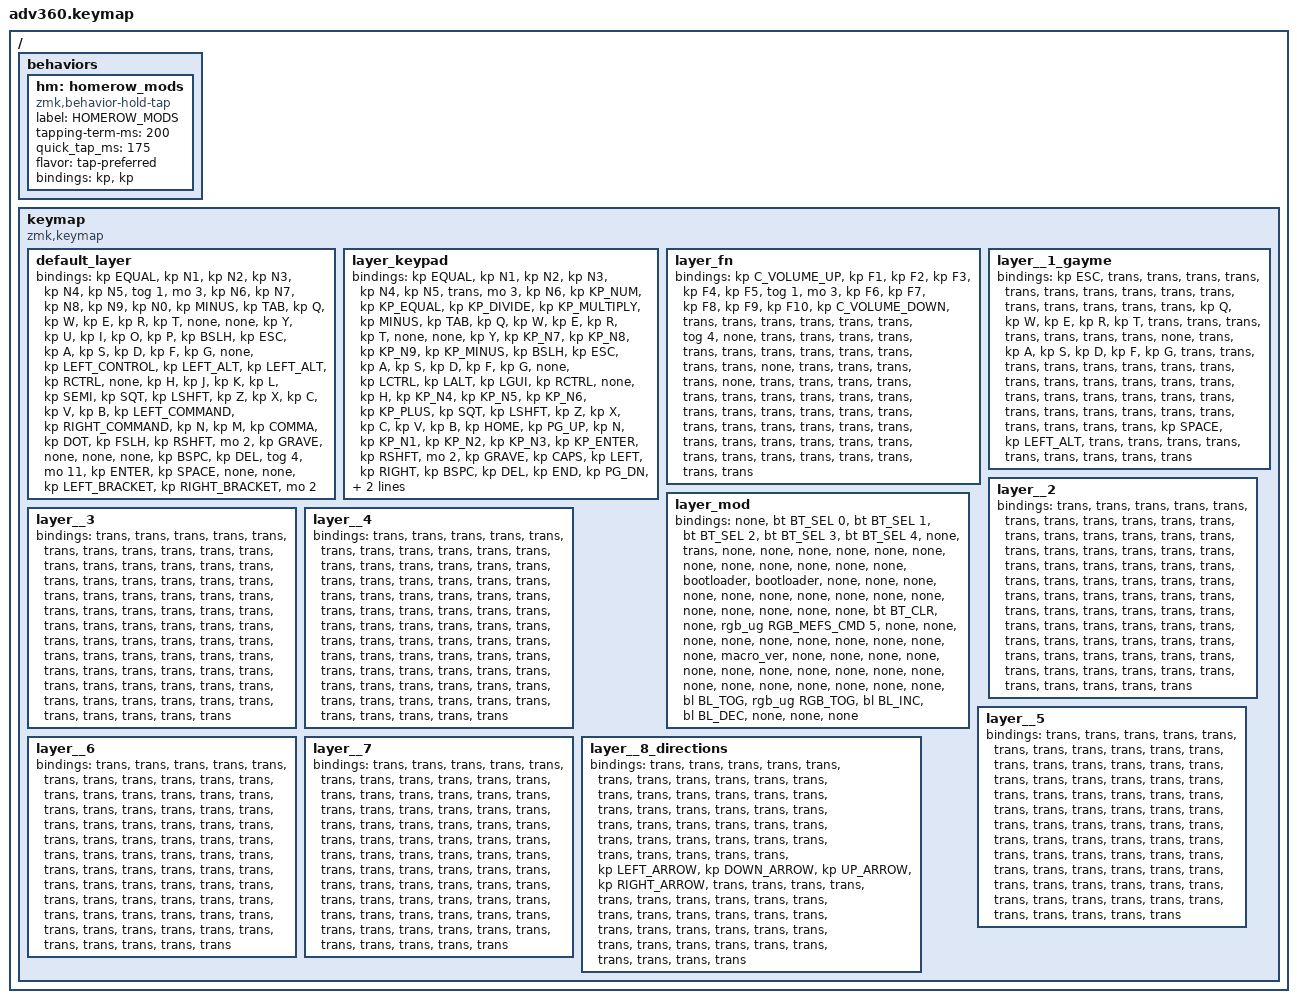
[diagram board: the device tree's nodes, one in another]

/*
 * Copyright (c) 2020 The ZMK Contributors
 *
 * SPDX-License-Identifier: MIT
 */


/* THIS FILE WAS GENERATED!
 *
 * This file was generated automatically. You may or may not want to
 * edit it directly.
 */

#include <behaviors.dtsi>
#include <dt-bindings/zmk/keys.h>
#include <dt-bindings/zmk/bt.h>
#include <dt-bindings/zmk/rgb.h>
#include <dt-bindings/zmk/backlight.h>

/ {
  behaviors {
    #include "macros.dtsi"
    #include "version.dtsi"

    hm: homerow_mods {
        compatible = "zmk,behavior-hold-tap";
        label = "HOMEROW_MODS";
        #binding-cells = <2>;
        tapping-term-ms = <200>;
        quick_tap_ms = <175>;
        flavor = "tap-preferred";
        bindings = <&kp>, <&kp>;
    };
  };

    keymap {
        compatible = "zmk,keymap";


        default_layer {
            bindings = <
 &kp EQUAL     &kp N1  &kp N2  &kp N3  &kp N4  &kp N5              &tog 1                                                                                        &mo 3  &kp N6  &kp N7     &kp N8            &kp N9             &kp N0  &kp MINUS
   &kp TAB      &kp Q   &kp W   &kp E   &kp R   &kp T               &none                                                                                        &none   &kp Y   &kp U      &kp I             &kp O              &kp P   &kp BSLH
   &kp ESC      &kp A   &kp S   &kp D   &kp F   &kp G               &none  &kp LEFT_CONTROL      &kp LEFT_ALT                       &kp LEFT_ALT  &kp RCTRL      &none   &kp H   &kp J      &kp K             &kp L           &kp SEMI    &kp SQT
 &kp LSHFT      &kp Z   &kp X   &kp C   &kp V   &kp B                                        &kp LEFT_COMMAND                  &kp RIGHT_COMMAND                         &kp N   &kp M  &kp COMMA           &kp DOT           &kp FSLH  &kp RSHFT
     &mo 2  &kp GRAVE   &none   &none   &none                    &kp BSPC           &kp DEL            &tog 4                             &mo 11  &kp ENTER  &kp SPACE           &none      &none  &kp LEFT_BRACKET  &kp RIGHT_BRACKET      &mo 2
            >;
        };

        layer_keypad {
            bindings = <
 &kp EQUAL     &kp N1    &kp N2    &kp N3     &kp N4  &kp N5              &trans                                                                 &mo 3  &kp N6  &kp KP_NUM  &kp KP_EQUAL  &kp KP_DIVIDE  &kp KP_MULTIPLY  &kp MINUS
   &kp TAB      &kp Q     &kp W     &kp E      &kp R   &kp T               &none                                                                 &none   &kp Y   &kp KP_N7     &kp KP_N8      &kp KP_N9     &kp KP_MINUS   &kp BSLH
   &kp ESC      &kp A     &kp S     &kp D      &kp F   &kp G               &none  &kp LCTRL  &kp LALT                   &kp LGUI  &kp RCTRL      &none   &kp H   &kp KP_N4     &kp KP_N5      &kp KP_N6      &kp KP_PLUS    &kp SQT
 &kp LSHFT      &kp Z     &kp X     &kp C      &kp V   &kp B                                 &kp HOME                  &kp PG_UP                         &kp N   &kp KP_N1     &kp KP_N2      &kp KP_N3     &kp KP_ENTER  &kp RSHFT
     &mo 2  &kp GRAVE  &kp CAPS  &kp LEFT  &kp RIGHT                    &kp BSPC    &kp DEL   &kp END                  &kp PG_DN  &kp ENTER  &kp KP_N0              &kp UP      &kp DOWN     &kp KP_DOT         &kp RBKT      &mo 2
            >;
        };

        layer_fn {
            bindings = <
 &kp C_VOLUME_UP  &kp F1  &kp F2  &kp F3  &kp F4  &kp F5            &tog 1                                                   &mo 3  &kp F6  &kp F7  &kp F8  &kp F9  &kp F10  &kp C_VOLUME_DOWN
          &trans  &trans  &trans  &trans  &trans  &trans            &tog 4                                                   &none  &trans  &trans  &trans  &trans   &trans             &trans
          &trans  &trans  &trans  &trans  &trans  &trans             &none  &trans  &trans                  &trans  &trans   &none  &trans  &trans  &trans  &trans   &trans             &trans
          &trans  &trans  &trans  &trans  &trans  &trans                            &trans                  &trans                  &trans  &trans  &trans  &trans   &trans             &trans
          &trans  &trans  &trans  &trans  &trans                    &trans  &trans  &trans                  &trans  &trans  &trans          &trans  &trans  &trans   &trans             &trans
            >;
        };

        layer_mod {
            bindings = <
  &none  &bt BT_SEL 0  &bt BT_SEL 1  &bt BT_SEL 2  &bt BT_SEL 3  &bt BT_SEL 4                  &none                                                                          &trans   &none       &none       &none   &none   &none   &none
  &none         &none         &none         &none         &none         &none            &bootloader                                                                     &bootloader   &none       &none       &none   &none   &none   &none
  &none         &none         &none         &none         &none         &none                  &none   &none   &none                  &bt BT_CLR       &none  &rgb_ug RGB_MEFS_CMD 5   &none       &none       &none   &none   &none   &none
  &none         &none         &none         &none    &macro_ver         &none                                  &none                       &none                                       &none       &none       &none   &none   &none   &none
  &none         &none         &none         &none         &none                                &none   &none   &none                       &none  &bl BL_TOG         &rgb_ug RGB_TOG          &bl BL_INC  &bl BL_DEC   &none   &none   &none
            >;
        };

        layer__1_gayme {
            bindings = <
 &kp ESC  &trans  &trans  &trans  &trans  &trans               &trans                                                        &trans  &trans  &trans  &trans  &trans  &trans  &trans
  &trans  &trans   &kp Q   &kp W   &kp E   &kp R                &kp T                                                        &trans  &trans  &trans  &trans  &trans  &trans  &trans
   &none  &trans   &kp A   &kp S   &kp D   &kp F                &kp G        &trans  &trans                  &trans  &trans  &trans  &trans  &trans  &trans  &trans  &trans  &trans
  &trans  &trans  &trans  &trans  &trans  &trans                                     &trans                  &trans                  &trans  &trans  &trans  &trans  &trans  &trans
  &trans  &trans  &trans  &trans  &trans                    &kp SPACE  &kp LEFT_ALT  &trans                  &trans  &trans  &trans          &trans  &trans  &trans  &trans  &trans
            >;
        };

        layer__2 {
            bindings = <
 &trans  &trans  &trans  &trans  &trans  &trans            &trans                                                  &trans  &trans  &trans  &trans  &trans  &trans  &trans
 &trans  &trans  &trans  &trans  &trans  &trans            &trans                                                  &trans  &trans  &trans  &trans  &trans  &trans  &trans
 &trans  &trans  &trans  &trans  &trans  &trans            &trans  &trans  &trans                  &trans  &trans  &trans  &trans  &trans  &trans  &trans  &trans  &trans
 &trans  &trans  &trans  &trans  &trans  &trans                            &trans                  &trans                  &trans  &trans  &trans  &trans  &trans  &trans
 &trans  &trans  &trans  &trans  &trans                    &trans  &trans  &trans                  &trans  &trans  &trans          &trans  &trans  &trans  &trans  &trans
            >;
        };

        layer__3 {
            bindings = <
 &trans  &trans  &trans  &trans  &trans  &trans            &trans                                                  &trans  &trans  &trans  &trans  &trans  &trans  &trans
 &trans  &trans  &trans  &trans  &trans  &trans            &trans                                                  &trans  &trans  &trans  &trans  &trans  &trans  &trans
 &trans  &trans  &trans  &trans  &trans  &trans            &trans  &trans  &trans                  &trans  &trans  &trans  &trans  &trans  &trans  &trans  &trans  &trans
 &trans  &trans  &trans  &trans  &trans  &trans                            &trans                  &trans                  &trans  &trans  &trans  &trans  &trans  &trans
 &trans  &trans  &trans  &trans  &trans                    &trans  &trans  &trans                  &trans  &trans  &trans          &trans  &trans  &trans  &trans  &trans
            >;
        };

        layer__4 {
            bindings = <
 &trans  &trans  &trans  &trans  &trans  &trans            &trans                                                  &trans  &trans  &trans  &trans  &trans  &trans  &trans
 &trans  &trans  &trans  &trans  &trans  &trans            &trans                                                  &trans  &trans  &trans  &trans  &trans  &trans  &trans
 &trans  &trans  &trans  &trans  &trans  &trans            &trans  &trans  &trans                  &trans  &trans  &trans  &trans  &trans  &trans  &trans  &trans  &trans
 &trans  &trans  &trans  &trans  &trans  &trans                            &trans                  &trans                  &trans  &trans  &trans  &trans  &trans  &trans
 &trans  &trans  &trans  &trans  &trans                    &trans  &trans  &trans                  &trans  &trans  &trans          &trans  &trans  &trans  &trans  &trans
            >;
        };

        layer__5 {
            bindings = <
 &trans  &trans  &trans  &trans  &trans  &trans            &trans                                                  &trans  &trans  &trans  &trans  &trans  &trans  &trans
 &trans  &trans  &trans  &trans  &trans  &trans            &trans                                                  &trans  &trans  &trans  &trans  &trans  &trans  &trans
 &trans  &trans  &trans  &trans  &trans  &trans            &trans  &trans  &trans                  &trans  &trans  &trans  &trans  &trans  &trans  &trans  &trans  &trans
 &trans  &trans  &trans  &trans  &trans  &trans                            &trans                  &trans                  &trans  &trans  &trans  &trans  &trans  &trans
 &trans  &trans  &trans  &trans  &trans                    &trans  &trans  &trans                  &trans  &trans  &trans          &trans  &trans  &trans  &trans  &trans
            >;
        };

        layer__6 {
            bindings = <
 &trans  &trans  &trans  &trans  &trans  &trans            &trans                                                  &trans  &trans  &trans  &trans  &trans  &trans  &trans
 &trans  &trans  &trans  &trans  &trans  &trans            &trans                                                  &trans  &trans  &trans  &trans  &trans  &trans  &trans
 &trans  &trans  &trans  &trans  &trans  &trans            &trans  &trans  &trans                  &trans  &trans  &trans  &trans  &trans  &trans  &trans  &trans  &trans
 &trans  &trans  &trans  &trans  &trans  &trans                            &trans                  &trans                  &trans  &trans  &trans  &trans  &trans  &trans
 &trans  &trans  &trans  &trans  &trans                    &trans  &trans  &trans                  &trans  &trans  &trans          &trans  &trans  &trans  &trans  &trans
            >;
        };

        layer__7 {
            bindings = <
 &trans  &trans  &trans  &trans  &trans  &trans            &trans                                                  &trans  &trans  &trans  &trans  &trans  &trans  &trans
 &trans  &trans  &trans  &trans  &trans  &trans            &trans                                                  &trans  &trans  &trans  &trans  &trans  &trans  &trans
 &trans  &trans  &trans  &trans  &trans  &trans            &trans  &trans  &trans                  &trans  &trans  &trans  &trans  &trans  &trans  &trans  &trans  &trans
 &trans  &trans  &trans  &trans  &trans  &trans                            &trans                  &trans                  &trans  &trans  &trans  &trans  &trans  &trans
 &trans  &trans  &trans  &trans  &trans                    &trans  &trans  &trans                  &trans  &trans  &trans          &trans  &trans  &trans  &trans  &trans
            >;
        };

        layer__8_directions {
            bindings = <
 &trans  &trans  &trans  &trans  &trans  &trans            &trans                                                  &trans          &trans          &trans        &trans           &trans  &trans  &trans
 &trans  &trans  &trans  &trans  &trans  &trans            &trans                                                  &trans          &trans          &trans        &trans           &trans  &trans  &trans
 &trans  &trans  &trans  &trans  &trans  &trans            &trans  &trans  &trans                  &trans  &trans  &trans  &kp LEFT_ARROW  &kp DOWN_ARROW  &kp UP_ARROW  &kp RIGHT_ARROW  &trans  &trans
 &trans  &trans  &trans  &trans  &trans  &trans                            &trans                  &trans                          &trans          &trans        &trans           &trans  &trans  &trans
 &trans  &trans  &trans  &trans  &trans                    &trans  &trans  &trans                  &trans  &trans  &trans                          &trans        &trans           &trans  &trans  &trans
            >;
        };

    };
};
